AUTOSAR XML (schema 4-0-3)
package /ComponentTypes
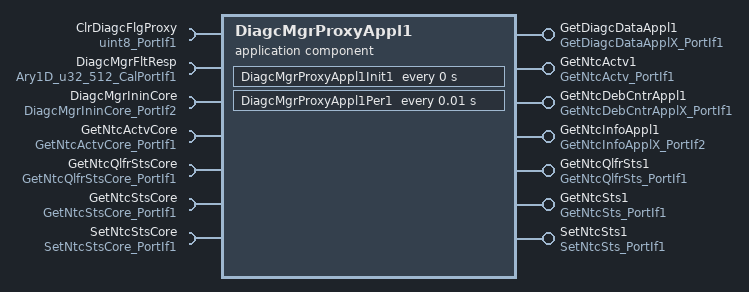
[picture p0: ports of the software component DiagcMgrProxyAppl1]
  application sw component type DiagcMgrProxyAppl1
    7 x provide port, all with server-com-spec{operation=Oper, queue-length=1}:
      GetDiagcDataAppl1: provided-interface=GetDiagcDataApplX_PortIf1
      GetNtcActv1: provided-interface=GetNtcActv_PortIf1
      GetNtcDebCntrAppl1: provided-interface=GetNtcDebCntrApplX_PortIf1
      GetNtcInfoAppl1: provided-interface=GetNtcInfoApplX_PortIf2
      GetNtcQlfrSts1: provided-interface=GetNtcQlfrSts_PortIf1
      GetNtcSts1: provided-interface=GetNtcSts_PortIf1
      SetNtcSts1: provided-interface=SetNtcSts_PortIf1
    7 x require port:
      ClrDiagcFlgProxy: nonqueued-receiver-com-spec{data-element=Val, filter=data-filter-type=ALWAYS, init-value=0}, required-interface=uint8_PortIf1
      DiagcMgrFltResp: parameter-require-com-spec{init-value=[0, 2147487488, 2147487488, 2147487488, 2147487488, 2147487488, 2147487488, 2147487488, 2147487488, 2147487488, 2147487488, 2147487488, 2147487488, 2147487488, 2147487488, 2147487488, 2147487488, 2147487488, 2147487488, 2147487488, 2147487488, 2147487488, 2147487488, 2147487488, 2147487488, 2147487488, 2147487488, 2147487488, 2147487488, 2147487488, 2147487488, 2147487488, 2147487488, 2147487488, 2147487488, 2147487488, 2147487488, 2147487488, 2147487488, 2147487488, 2147487488, 2147487488, 2147487488, 2147487488, 2147487488, 2147487488, 2147487488, 2147487488, 2147487488, 2147487488, 2147487488, 2147487488, 2147487488, 2147487488, 2147487488, 2147487488, 2147487488, 2147487488, 2147487488, 2147487488, 2147487488, 2147487488, 2147487488, 2147487488, 2147487488, 2147487488, 2147487488, 2147487488, 2147487488, 2147487488, 2147487488, 2147487488, 2147487488, 2147487488, 2147487488, 2147487488, 2147487488, 2147487488, 2147487488, 2147487488, 2147487488, 2147487488, 2147487488, 2147487488, 2147487488, 2147487488, 2147487488, 2147487488, 2147487488, 2147487488, 2147487488, 2147487488, 2147487488, 2147487488, 2147487488, 2147487488, 2147487488, 2147487488, 2147487488, 2147487488, 2147487488, 2147487488, 2147487488, 2147487488, 2147487488, 2147487488, 2147487488, 2147487488, 2147487488, 2147487488, 2147487488, 2147487488, 2147487488, 2147487488, 2147487488, 2147487488, 2147487488, 2147487488, 2147487488, 2147487488, 2147487488, 2147487488, 2147487488, 2147487488, 2147487488, 2147487488, 2147487488, 2147487488, 2147487488, 2147487488, 2147487488, 2147487488, 2147487488, 2147487488, 2147487488, 2147487488, 2147487488, 2147487488, 2147487488, 2147487488, 2147487488, 2147487488, 2147487488, 2147487488, 2147487488, 2147487488, 2147487488, 2147487488, 2147487488, 2147487488, 2147487488, 2147487488, 2147487488, 2147487488, 2147487488, 2147487488, 2147487488, 2147487488, 2147487488, 2147487488, 2147487488, 2147487488, 2147487488, 2147487488, 2147487488, 2147487488, 2147487488, 2147487488, 2147487488, 2147487488, 2147487488, 2147487488, 2147487488, 2147487488, 2147487488, 2147487488, 2147487488, 2147487488, 2147487488, 2147487488, 2147487488, 2147487488, 2147487488, 2147487488, 2147487488, 2147487488, 2147487488, 2147487488, 2147487488, 2147487488, 2147487488, 2147487488, 2147487488, 2147487488, 2147487488, 2147487488, 2147487488, 2147487488, 2147487488, 2147487488, 2147487488, 2147487488, 2147487488, 2147487488, 2147487488, 2147487488, 2147487488, 2147487488, 2147487488, 2147487488, 2147487488, 2147487488, 2147487488, 2147487488, 2147487488, 2147487488, 2147487488, 2147487488, 2147487488, 2147487488, 2147487488, 2147487488, 2147487488, 2147487488, 2147487488, 2147487488, 2147487488, 2147487488, 2147487488, 2147487488, 2147487488, 2147487488, 2147487488, 2147487488, 2147487488, 2147487488, 2147487488, 2147487488, 2147487488, 2147487488, 2147487488, 2147487488, 2147487488, 2147487488, 2147487488, 2147487488, 2147487488, 2147487488, 2147487488, 2147487488, 2147487488, 2147487488, 2147487488, 2147487488, 2147487488, 2147487488, 2147487488, 2147487488, 2147487488, 2147487488, 2147487488, 2147487488, 2147487488, 2147487488, 2147487488, 2147487488, 2147487488, 2147487488, 2147487488, 2147487488, 2147487488, 2147487488, 2147487488, 2147487488, 2147487488, 2147487488, 2147487488, 2147487488, 2147487488, 2147487488, 2147487488, 2147487488, 2147487488, 2147487488, 2147487488, 2147487488, 2147487488, 2147487488, 2147487488, 2147487488, 2147487488, 2147487488, 2147487488, 2147487488, 2147487488, 2147487488, 2147487488, 2147487488, 2147487488, 2147487488, 2147487488, 2147487488, 2147487488, 2147487488, 2147487488, 2147487488, 2147487488, 2147487488, 2147487488, 2147487488, 2147487488, 2147487488, 2147487488, 2147487488, 2147487488, 2147487488, 2147487488, 2147487488, 2147487488, 2147487488, 2147487488, 2147487488, 2147487488, 2147487488, 2147487488, 2147487488, 2147487488, 2147487488, 2147487488, 2147487488, 2147487488, 2147487488, 2147487488, 2147487488, 2147487488, 2147487488, 2147487488, 2147487488, 2147487488, 2147487488, 2147487488, 2147487488, 2147487488, 2147487488, 2147487488, 2147487488, 2147487488, 2147487488, 2147487488, 2147487488, 2147487488, 2147487488, 2147487488, 2147487488, 2147487488, 2147487488, 2147487488, 2147487488, 2147487488, 2147487488, 2147487488, 2147487488, 2147487488, 2147487488, 2147487488, 2147487488, 2147487488, 2147487488, 2147487488, 2147487488, 2147487488, 2147487488, 2147487488, 2147487488, 2147487488, 2147487488, 2147487488, 2147487488, 2147487488, 2147487488, 2147487488, 2147487488, 2147487488, 2147487488, 2147487488, 2147487488, 2147487488, 2147487488, 2147487488, 2147487488, 2147487488, 2147487488, 2147487488, 2147487488, 2147487488, 2147487488, 2147487488, 2147487488, 2147487488, 2147487488, 2147487488, 2147487488, 2147487488, 2147487488, 2147487488, 2147487488, 2147487488, 2147487488, 2147487488, 2147487488, 2147487488, 2147487488, 2147487488, 2147487488, 2147487488, 2147487488, 2147487488, 2147487488, 2147487488, 2147487488, 2147487488, 2147487488, 2147487488, 2147487488, 2147487488, 2147487488, 2147487488, 2147487488, 2147487488, 2147487488, 2147487488, 2147487488, 2147487488, 2147487488, 2147487488, 2147487488, 2147487488, 2147487488, 2147487488, 2147487488, 2147487488, 2147487488, 2147487488, 2147487488, 2147487488, 2147487488, 2147487488, 2147487488, 2147487488, 2147487488, 2147487488, 2147487488, 2147487488, 2147487488, 2147487488, 2147487488, 2147487488, 2147487488, 2147487488, 2147487488, 2147487488, 2147487488, 2147487488, 2147487488, 2147487488, 2147487488, 2147487488, 2147487488, 2147487488, 2147487488, 2147487488, 2147487488, 2147487488, 2147487488, 2147487488, 2147487488, 2147487488, 2147487488, 2147487488, 2147487488, 2147487488, 2147487488, 2147487488, 2147487488, 2147487488, 2147487488, 2147487488, 2147487488, 2147487488, 2147487488, 2147487488, 2147487488, 2147487488, 2147487488, 2147487488, 2147487488, 2147487488, 2147487488, 2147487488, 2147487488, 2147487488, 2147487488, 2147487488, 2147487488, 2147487488, 2147487488, 2147487488, 2147487488, 2147487488, 2147487488, 2147487488, 2147487488], parameter=Ary1D}, required-interface=Ary1D_u32_512_CalPortIf1
      DiagcMgrIninCore: required-interface=DiagcMgrIninCore_PortIf2
      GetNtcActvCore: required-interface=GetNtcActvCore_PortIf1
      GetNtcQlfrStsCore: required-interface=GetNtcQlfrStsCore_PortIf1
      GetNtcStsCore: required-interface=GetNtcStsCore_PortIf1
      SetNtcStsCore: required-interface=SetNtcStsCore_PortIf1
    behavior DiagcMgrProxyAppl1_InternalBehavior
      exclusive area DiagcMgrProxyAppl1
      ar-typed-per-instance-memorys:
        5 x data:
          DiagcData1: sw-calibration-access=READ-ONLY, type=DiagcDataRec1
          DiagcMgrNtcInfo1Ary: type=Ary1D_NtcInfoRec4_DiagcMgrProxyAppl1
          DiagcMgrNtcInfo1DebCntrAry: type=Ary1D_s16_DiagcMgrProxyAppl1
          PrevClrNtcFlg1: sw-calibration-access=READ-ONLY, type=uint8
          ProxySetNtcData1: sw-calibration-access=READ-ONLY, type=DiagcDataRec1
      timing event DiagcMgrProxyAppl1_InitEvent: start-on-event=DiagcMgrProxyAppl1Init1, period=0
      timing event TMT_DiagcMgrProxyAppl1Per1: start-on-event=DiagcMgrProxyAppl1Per1, period=0.01
      7 x operation invoked event:
        OIT_GetDiagcDataAppl1_Oper_GetDiagcDataAppl1_Oper: start-on-event=GetDiagcDataAppl1_Oper, operation=GetDiagcDataAppl1.Oper
        OIT_GetNtcActv1_Oper_GetNtcActv1_Oper: start-on-event=GetNtcActv1_Oper, operation=GetNtcActv1.Oper
        OIT_GetNtcDebCntrAppl1_Oper_GetNtcDebCntrAppl1_Oper: start-on-event=GetNtcDebCntrAppl1_Oper, operation=GetNtcDebCntrAppl1.Oper
        OIT_GetNtcInfoAppl1_Oper_GetNtcInfoAppl1_Oper: start-on-event=GetNtcInfoAppl1_Oper, operation=GetNtcInfoAppl1.Oper
        OIT_GetNtcQlfrSts1_Oper_GetNtcQlfrSts1_Oper: start-on-event=GetNtcQlfrSts1_Oper, operation=GetNtcQlfrSts1.Oper
        OIT_GetNtcSts1_Oper_GetNtcSts1_Oper: start-on-event=GetNtcSts1_Oper, operation=GetNtcSts1.Oper
        OIT_SetNtcSts1_Oper_SetNtcSts1_Oper: start-on-event=SetNtcSts1_Oper, operation=SetNtcSts1.Oper
      9 x runnable:
        DiagcMgrProxyAppl1Init1
          sync call SC_DiagcMgrIninCore_Oper: operation=DiagcMgrIninCore.Oper, timeout=0
        DiagcMgrProxyAppl1Per1: can-enter-exclusive-area=DiagcMgrProxyAppl1
          data-receive-point-by-arguments:
            access REC_ClrNtcFlg_Val: accessed-variable=ClrDiagcFlgProxy.Val
        GetDiagcDataAppl1_Oper
        GetNtcActv1_Oper: can-be-invoked-concurrently=true
          sync call SC_GetNtcActvCore_Oper: operation=GetNtcActvCore.Oper, timeout=0
        GetNtcDebCntrAppl1_Oper
        GetNtcInfoAppl1_Oper
        GetNtcQlfrSts1_Oper: can-be-invoked-concurrently=true
          sync call SC_GetNtcQlfrStsCore_Oper: operation=GetNtcQlfrStsCore.Oper, timeout=0
        GetNtcSts1_Oper: can-be-invoked-concurrently=true
          sync call SC_GetNtcStsCore_Oper: operation=GetNtcStsCore.Oper, timeout=0
        SetNtcSts1_Oper: can-be-invoked-concurrently=true
          sync call SC_SetNtcStsCore_Oper: operation=SetNtcStsCore.Oper, timeout=0
  swc implementation DiagcMgrProxyAppl1_Implementation: behavior=DiagcMgrProxyAppl1_InternalBehavior
    code-descriptors:
      code Default: artifact-descriptors=autosar-engineering-object={short-label=Default, category=SWSRC}
